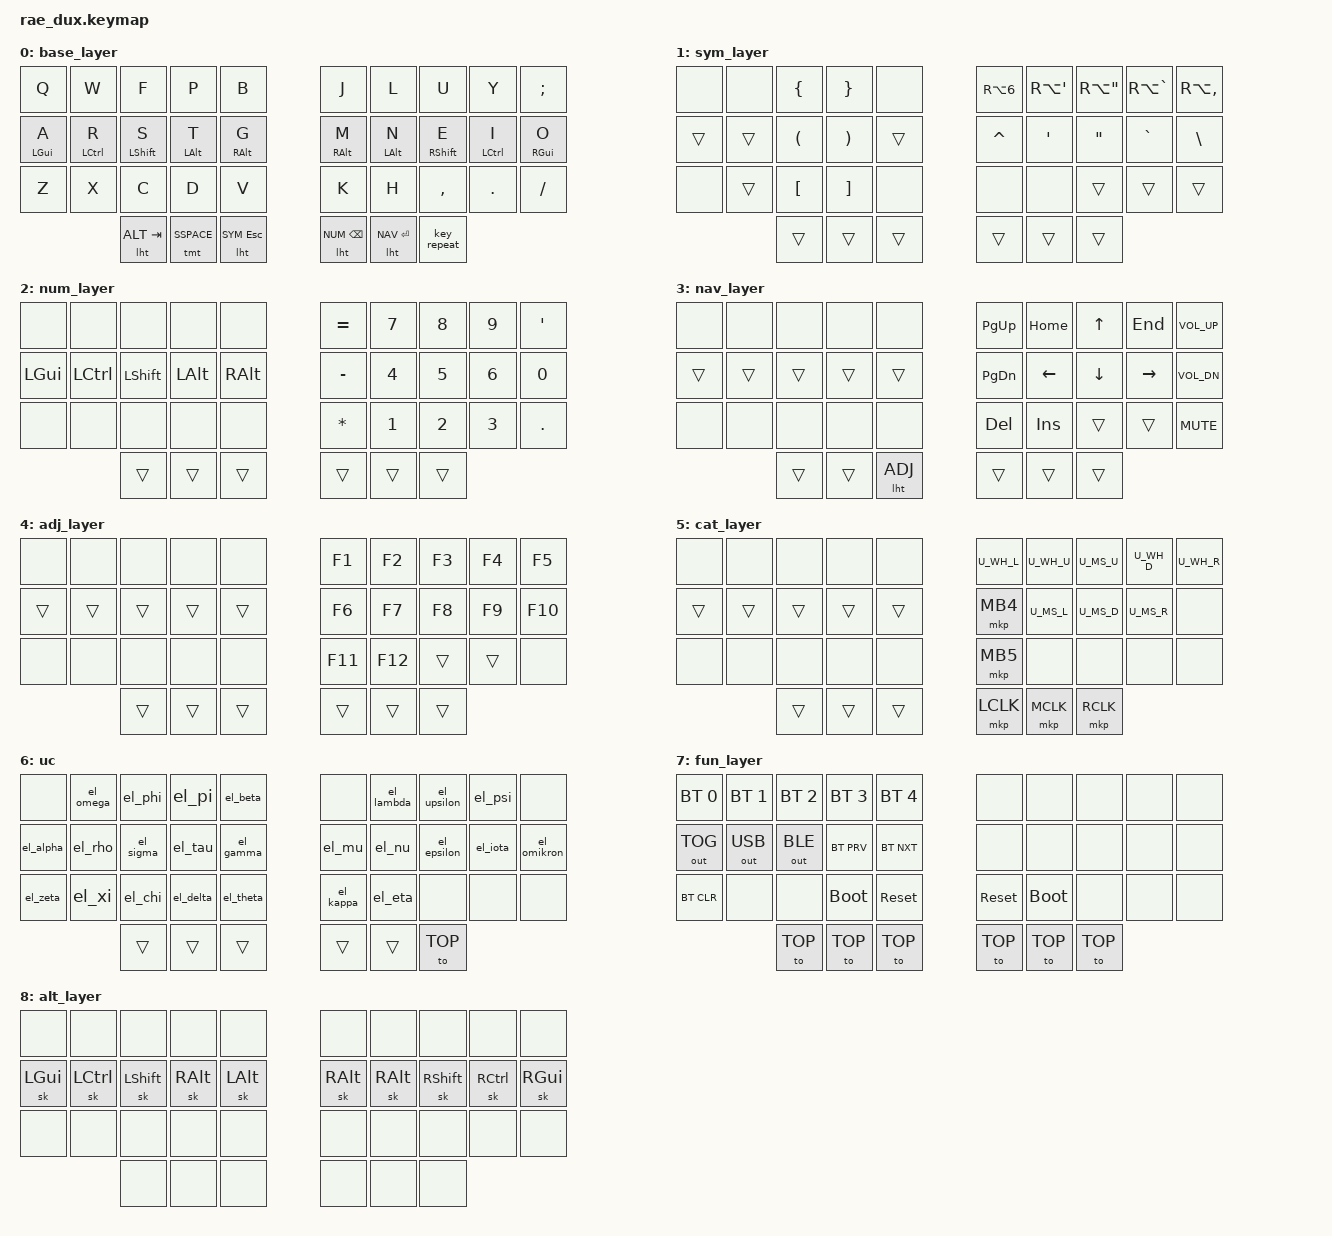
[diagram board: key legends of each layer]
/*
 * Copyright (c) 2021 The ZMK Contributors
 *
 * SPDX-License-Identifier: MIT
 */

#include <behaviors.dtsi>
#include <dt-bindings/zmk/outputs.h>
#include <dt-bindings/zmk/keys.h>
#include <dt-bindings/zmk/bt.h>
#define HOST_OS 1 // allow unicode on linux
#include "helper.h"
#include "greek.dtsi"
#include "mouse.dtsi"

#define TOP  0
#define SYM  1
#define NUM  2
#define NAV  3
#define ADJ  4
#define CAT  5
#define MAT  6
#define FUN  7
#define ALT  8

/* stick key */
&sk {
    release-after-ms = <750>;
    quick-release;
};

&caps_word {
    continue-list = <UNDERSCORE MINUS BSPC>;
};

// smart-mouse, requires PR #1366
ZMK_BEHAVIOR(smart_mouse, tri_state,
    bindings = <&tog CAT>, <&none>, <&tog CAT>;
    ignored-key-positions = <5 6 7 8 9 15 16 17 18 25 33 34 35>;
    ignored-layers = <CAT>;
)


 HOLD_TAP(hrm,  "tap-unless-interrupted", 50, 50, &kp, &kp)
//HOLD_TAP(hrm,  "balanced", 50, 50, &kp, &kp)
HOLD_TAP(tmt,  "hold-preferred", 200, 200, &kp, &kp)
HOLD_TAP(lht,  "hold-preferred", 200, 200, &mo, &kp)


MACRO(sub_arrow, 30, 30, &kp MINUS &kp GT)
MACRO(fat_arrow, 30, 30, &kp EQUAL &kp GT)
MACRO(eli_arrow, 30, 30, &kp TILDE &kp GT)
MACRO(tmux,      30, 30, &sk LCTRL &kp B)

/*                KEY POSITIONS
  ╭────────────────────╮ ╭────────────────────╮
  │  0   1   2   3   4 │ │  5   6   7   8   9 │
  │ 10  11  12  13  14 │ │ 15  16  17  18  19 │
  │ 20  21  22  23  24 │ │ 25  26  27  28  29 │
  ╰───────╮ 30  31  32 │ │ 33  34  35 ╭───────╯
          ╰────────────╯ ╰────────────╯        */
ZMK_COMBO(combo_caps,      &caps_word, 31 34, TOP, 50)
ZMK_COMBO(combo_tmux,      &tmux,      13 14, TOP, 50)
ZMK_COMBO(combo_sub_arrow, &sub_arrow, 18 19, SYM, 50)
ZMK_COMBO(combo_fat_arrow, &fat_arrow,  8  9, SYM, 50)
ZMK_COMBO(combo_eli_arrow, &eli_arrow, 28 29, SYM, 50)

//ZMK_COMBO(combo_cat_layer, &to CAT, 3 4, TOP, 50)
ZMK_COMBO(combo_cat_layer, &smart_mouse,   3 4, TOP, 50)
ZMK_COMBO(combo_fun_layer, &to FUN,  16  17  18  19, TOP, 50)
ZMK_COMBO(combo_mat_layer, &to MAT,  26  27  28  29, TOP, 50)

//&key_repeat {
//    usage-pages = <HID_USAGE_KEY HID_USAGE_CONSUMER>;
//};

#define SSPACE LSHFT SPACE

ZMK_LAYER(base_layer,
  // ╭─────────────┬─────────────┬─────────────┬─────────────┬─────────────╮   ╭─────────────┬─────────────┬─────────────┬─────────────┬─────────────╮
      &kp Q         &kp W         &kp F         &kp P         &kp B             &kp J         &kp L         &kp U         &kp Y         &kp SEMI
  // ├─────────────┼─────────────┼─────────────┼─────────────┼─────────────┤   ├─────────────┼─────────────┼─────────────┼─────────────┼─────────────┤
      &hrm LGUI A   &hrm LCTRL R  &hrm LSHFT S  &hrm LALT T   &hrm RALT G       &hrm RALT M   &hrm LALT N   &hrm RSHFT E  &hrm LCTRL I  &hrm RGUI O
  // ├─────────────┼─────────────┼─────────────┼─────────────┼─────────────┤   ├─────────────┼─────────────┼─────────────┼─────────────┼─────────────┤
      &kp Z         &kp X         &kp C         &kp D         &kp V             &kp K         &kp H         &kp COMMA     &kp DOT       &kp FSLH
  // ╰─────────────┴─────────────┼─────────────┼─────────────┼─────────────┤   ├─────────────┼─────────────┼─────────────┼─────────────┴─────────────╯
                                  &lht ALT TAB  &tmt SSPACE   &lht SYM ESC      &lht NUM BSPC &lht NAV RET  &key_repeat
  //                             ╰─────────────┴─────────────┴─────────────╯   ╰─────────────┴─────────────┴─────────────╯
)
ZMK_LAYER(sym_layer,
  // ╭─────────────┬─────────────┬─────────────┬─────────────┬─────────────╮   ╭─────────────┬─────────────┬─────────────┬─────────────┬─────────────╮
      &none         &none         &kp LBRC      &kp RBRC      &none             &kp RA(N6)    &kp RA(SQT)   &kp RA(DQT)   &kp RA(GRAVE) &kp RA(COMMA)
  // ├─────────────┼─────────────┼─────────────┼─────────────┼─────────────┤   ├─────────────┼─────────────┼─────────────┼─────────────┼─────────────┤
      &trans        &trans        &kp LPAR      &kp RPAR      &trans            &kp CARET     &kp SQT       &kp DQT       &kp GRAVE     &kp BSLH
  // ├─────────────┼─────────────┼─────────────┼─────────────┼─────────────┤   ├─────────────┼─────────────┼─────────────┼─────────────┼─────────────┤
      &none         &trans        &kp LBKT      &kp RBKT      &none             &none         &none         &trans        &trans        &trans
  // ╰─────────────┴─────────────┼─────────────┼─────────────┼─────────────┤   ├─────────────┼─────────────┼─────────────┼─────────────┴─────────────╯
                                  &trans        &trans        &trans            &trans        &trans        &trans
  //                             ╰─────────────┴─────────────┴─────────────╯   ╰─────────────┴─────────────┴─────────────╯
)
ZMK_LAYER(num_layer,
  // ╭─────────────┬─────────────┬─────────────┬─────────────┬─────────────╮   ╭─────────────┬─────────────┬─────────────┬─────────────┬─────────────╮
      &none         &none         &none         &none         &none             &kp EQUAL     &kp N7        &kp N8        &kp N9        &kp SQT
  // ├─────────────┼─────────────┼─────────────┼─────────────┼─────────────┤   ├─────────────┼─────────────┼─────────────┼─────────────┼─────────────┤
      &kp LGUI      &kp LCTRL     &kp LSHFT     &kp LALT      &kp RALT          &kp MINUS     &kp N4        &kp N5        &kp N6        &kp N0
  // ├─────────────┼─────────────┼─────────────┼─────────────┼─────────────┤   ├─────────────┼─────────────┼─────────────┼─────────────┼─────────────┤
      &none         &none         &none         &none         &none             &kp ASTRK     &kp N1        &kp N2        &kp N3        &kp DOT
  // ╰─────────────┴─────────────┼─────────────┼─────────────┼─────────────┤   ├─────────────┼─────────────┼─────────────┼─────────────┴─────────────╯
                                  &trans        &trans        &trans            &trans        &trans        &trans
  //                             ╰─────────────┴─────────────┴─────────────╯   ╰─────────────┴─────────────┴─────────────╯

)
ZMK_LAYER(nav_layer,
  // ╭─────────────┬─────────────┬─────────────┬─────────────┬─────────────╮   ╭─────────────┬─────────────┬─────────────┬─────────────┬─────────────╮
      &none         &none         &none         &none         &none             &kp PG_UP     &kp HOME      &kp UP        &kp END       &kp C_VOL_UP
  // ├─────────────┼─────────────┼─────────────┼─────────────┼─────────────┤   ├─────────────┼─────────────┼─────────────┼─────────────┼─────────────┤
      &trans        &trans        &trans        &trans        &trans            &kp PG_DN     &kp LEFT      &kp DOWN      &kp RIGHT     &kp C_VOL_DN
  // ├─────────────┼─────────────┼─────────────┼─────────────┼─────────────┤   ├─────────────┼─────────────┼─────────────┼─────────────┼─────────────┤
      &none         &none         &none         &none         &none             &kp DEL       &kp INSERT    &trans        &trans        &kp C_MUTE 
  // ╰─────────────┴─────────────┼─────────────┼─────────────┼─────────────┤   ├─────────────┼─────────────┼─────────────┼─────────────┴─────────────╯
                                  &trans        &trans        &lht ADJ          &trans        &trans        &trans
  //                             ╰─────────────┴─────────────┴─────────────╯   ╰─────────────┴─────────────┴─────────────╯
)
ZMK_LAYER(adj_layer,
  // ╭─────────────┬─────────────┬─────────────┬─────────────┬─────────────╮   ╭─────────────┬─────────────┬─────────────┬─────────────┬─────────────╮
      &none         &none         &none         &none         &none             &kp F1        &kp F2        &kp F3        &kp F4        &kp F5
  // ├─────────────┼─────────────┼─────────────┼─────────────┼─────────────┤   ├─────────────┼─────────────┼─────────────┼─────────────┼─────────────┤
      &trans        &trans        &trans        &trans        &trans            &kp F6        &kp F7        &kp F8        &kp F9        &kp F10
  // ├─────────────┼─────────────┼─────────────┼─────────────┼─────────────┤   ├─────────────┼─────────────┼─────────────┼─────────────┼─────────────┤
      &none         &none         &none         &none         &none             &kp F11       &kp F12       &trans        &trans        &none
  // ╰─────────────┴─────────────┼─────────────┼─────────────┼─────────────┤   ├─────────────┼─────────────┼─────────────┼─────────────┴─────────────╯
                                  &trans        &trans        &trans            &trans        &trans        &trans
  //                             ╰─────────────┴─────────────┴─────────────╯   ╰─────────────┴─────────────┴─────────────╯
)

ZMK_LAYER(cat_layer,
  // ╭─────────────┬─────────────┬─────────────┬─────────────┬─────────────╮   ╭─────────────┬─────────────┬─────────────┬─────────────┬─────────────╮
      &none         &none         &none         &none         &none             U_WH_L        U_WH_U        U_MS_U        U_WH_D        U_WH_R       
  // ├─────────────┼─────────────┼─────────────┼─────────────┼─────────────┤   ├─────────────┼─────────────┼─────────────┼─────────────┼─────────────┤
      &trans        &trans        &trans        &trans        &trans            &mkp MB4      U_MS_L        U_MS_D        U_MS_R        &none          
  // ├─────────────┼─────────────┼─────────────┼─────────────┼─────────────┤   ├─────────────┼─────────────┼─────────────┼─────────────┼─────────────┤
      &none         &none         &none         &none         &none             &mkp MB5      &none         &none         &none         &none          
  // ╰─────────────┴─────────────┼─────────────┼─────────────┼─────────────┤   ├─────────────┼─────────────┼─────────────┼─────────────┴─────────────╯
                                  &trans        &trans        &trans            &mkp LCLK     &mkp MCLK      &mkp RCLK
  //                             ╰─────────────┴─────────────┴─────────────╯   ╰─────────────┴─────────────┴─────────────╯
)

ZMK_LAYER(uc,
//  ╭─────────────┬─────────────┬─────────────┬─────────────┬─────────────╮   ╭─────────────┬─────────────┬─────────────┬─────────────┬─────────────╮
     &none         &el_omega     &el_phi       &el_pi        &el_beta          &none         &el_lambda    &el_upsilon   &el_psi       &none   
//  ├─────────────┼─────────────┼─────────────┼─────────────┼─────────────┤   ├─────────────┼─────────────┼─────────────┼─────────────┼─────────────┤
     &el_alpha     &el_rho       &el_sigma     &el_tau       &el_gamma         &el_mu        &el_nu        &el_epsilon   &el_iota      &el_omikron  
//  ├─────────────┼─────────────┼─────────────┼─────────────┼─────────────┤   ├─────────────┼─────────────┼─────────────┼─────────────┼─────────────┤
     &el_zeta      &el_xi        &el_chi       &el_delta     &el_theta         &el_kappa     &el_eta       &none         &none         &none       
//  ╰─────────────┼─────────────┴─────────────┼─────────────┼─────────────┤   ├─────────────┼─────────────┼─────────────┴───────────────────────────╯
                                  &trans        &trans        &trans            &trans        &trans        &to TOP
//                              ╰─────────────┴─────────────┴─────────────╯   ╰─────────────┴─────────────┴─────────────╯
)

ZMK_LAYER(fun_layer,
  // ╭─────────────┬─────────────┬─────────────┬─────────────┬─────────────╮   ╭─────────────┬─────────────┬─────────────┬─────────────┬─────────────╮
      &bt BT_SEL 0  &bt BT_SEL 1  &bt BT_SEL 2  &bt BT_SEL 3  &bt BT_SEL 4      &none         &none         &none         &none         &none
  // ├─────────────┼─────────────┼─────────────┼─────────────┼─────────────┤   ├─────────────┼─────────────┼─────────────┼─────────────┼─────────────┤
      &out OUT_TOG  &out OUT_USB  &out OUT_BLE  &bt BT_PRV    &bt BT_NXT        &none         &none         &none         &none         &none
  // ├─────────────┼─────────────┼─────────────┼─────────────┼─────────────┤   ├─────────────┼─────────────┼─────────────┼─────────────┼─────────────┤
      &bt BT_CLR    &none         &none         &bootloader   &sys_reset        &sys_reset    &bootloader   &none         &none         &none
  // ╰─────────────┴─────────────┼─────────────┼─────────────┼─────────────┤   ├─────────────┼─────────────┼─────────────┼─────────────┴─────────────╯
                                  &to TOP       &to TOP       &to TOP           &to TOP       &to TOP       &to TOP
  //                             ╰─────────────┴─────────────┴─────────────╯   ╰─────────────┴─────────────┴─────────────╯
)

ZMK_LAYER(alt_layer,
  // ╭─────────────┬─────────────┬─────────────┬─────────────┬─────────────╮   ╭─────────────┬─────────────┬─────────────┬─────────────┬─────────────╮
      &none         &none         &none         &none         &none             &none         &none         &none         &none         &none
  // ├─────────────┼─────────────┼─────────────┼─────────────┼─────────────┤   ├─────────────┼─────────────┼─────────────┼─────────────┼─────────────┤
      &sk LGUI      &sk LCTRL     &sk LSHIFT    &sk RALT      &sk LALT          &sk RALT      &sk RALT      &sk RSHFT     &sk RCTRL     &sk RGUI
  // ├─────────────┼─────────────┼─────────────┼─────────────┼─────────────┤   ├─────────────┼─────────────┼─────────────┼─────────────┼─────────────┤
      &none         &none         &none         &none         &none             &none         &none         &none         &none         &none
  // ╰─────────────┴─────────────┼─────────────┼─────────────┼─────────────┤   ├─────────────┼─────────────┼─────────────┼─────────────┴─────────────╯
                                  &none         &none         &none             &none         &none         &none
  //                             ╰─────────────┴─────────────┴─────────────╯   ╰─────────────┴─────────────┴─────────────╯
)


/* vim: set ft=c: */
